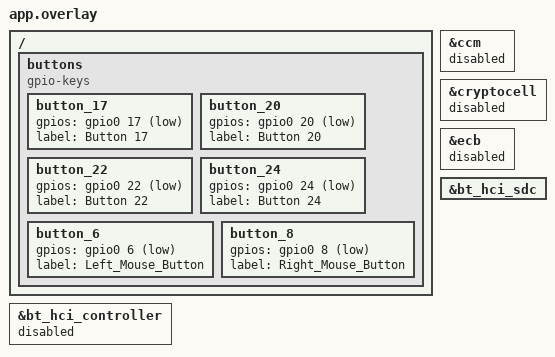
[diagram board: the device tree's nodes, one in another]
/ {
    buttons {
        compatible = "gpio-keys";
        #address-cells = <1>;
        #size-cells = <0>;

        button_17: button_17 {
            gpios = <&gpio0 17 (GPIO_PULL_UP | GPIO_ACTIVE_LOW)>;
            label = "Button 17";
        };
        button_20: button_20 {
            gpios = <&gpio0 20 (GPIO_PULL_UP | GPIO_ACTIVE_LOW)>;
            label = "Button 20";
        };
        button_22: button_22 {
            gpios = <&gpio0 22 (GPIO_PULL_UP | GPIO_ACTIVE_LOW)>;
            label = "Button 22";
        };
        button_24: button_24 {
            gpios = <&gpio0 24 (GPIO_PULL_UP | GPIO_ACTIVE_LOW)>;
            label = "Button 24";
        };
        button_6: button_6 {
            gpios = <&gpio0 6 (GPIO_PULL_UP | GPIO_ACTIVE_LOW)>;
            label = "Left_Mouse_Button";
        };
        button_8: button_8 {
            gpios = <&gpio0 8 (GPIO_PULL_UP | GPIO_ACTIVE_LOW)>;
            label = "Right_Mouse_Button";
        };
    };
};

// &spi1 {
//     status = "okay";
//     cs-gpios = <&gpio0 9 (GPIO_ACTIVE_LOW | GPIO_PULL_UP)>;  /* D9 - CS pin for device 0 */

//     pmw3389: pmw3389@0 {
//         compatible = "pixart,pmw3389";
//         reg = <0>;
//         spi-max-frequency = <2000000>;
//         resolution = <1600>;
//     };
// };

&ccm {
    status = "disabled";
};

&cryptocell {
    status = "disabled";
};

&ecb {
    status = "disabled";
};

&bt_hci_controller {
    status = "disabled";
};

&bt_hci_sdc {
    status = "okay";
};
